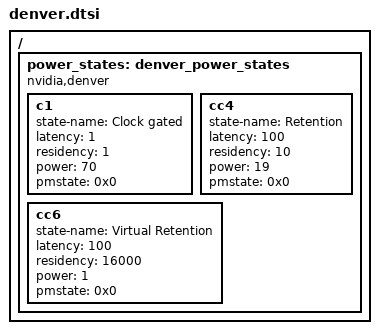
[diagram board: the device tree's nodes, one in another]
/ {
	power_states: denver_power_states {
		compatible = "nvidia,denver";

		c1 {
			state-name = "Clock gated";
			latency = <1>;
			residency = <1>;
			power = <70>;
			pmstate = <0x0>;
		};
		cc4 {
			state-name = "Retention";
			latency = <100>;
			residency = <10>;
			power = <19>;
			pmstate = <0x0>;
		};
		cc6 {
			state-name = "Virtual Retention";
			latency = <100>;
			residency = <16000>;
			power = <1>;
			pmstate = <0x0>;
		};

	};
};
